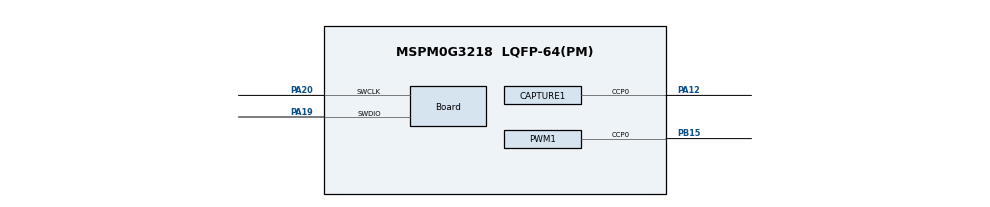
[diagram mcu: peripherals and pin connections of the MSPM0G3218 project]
//@cliArgs --device "MSPM0G321X" --package "LQFP-64(PM)" --part "Default"
//@v2CliArgs --device "MSPM0G3218" --package "LQFP-64(PM)"
// @cliArgs --board /ti/boards/LP_MSPM0G3218 --rtos nortos

/**
 * Import the modules used in this configuration.
 */
const CAPTURE  = scripting.addModule("/ti/driverlib/CAPTURE", {}, false);
const CAPTURE1 = CAPTURE.addInstance();
const PWM      = scripting.addModule("/ti/driverlib/PWM", {}, false);
const PWM1     = PWM.addInstance();

/**
 * Write custom configuration values to the imported modules.
 */
CAPTURE1.$name                      = "CAPTURE_0";
CAPTURE1.captMode                   = "COMBINED";
CAPTURE1.timerClkPrescale           = 256;
CAPTURE1.timerPeriod                = "524.29 ms";
CAPTURE1.interrupts                 = ["CC1_DN","ZERO"];
CAPTURE1.peripheral.ccp0Pin.$assign = "PA12";

const Board                       = scripting.addModule("/ti/driverlib/Board", {}, false);
Board.peripheral.$assign          = "DEBUGSS";
Board.peripheral.swclkPin.$assign = "PA20";
Board.peripheral.swdioPin.$assign = "PA19";

PWM1.$name                      = "PWM_0";
PWM1.ccIndex                    = [0];
PWM1.clockPrescale              = 256;
PWM1.peripheral.ccp0Pin.$assign = "PB15";
PWM1.PWM_CHANNEL_0.$name        = "ti_driverlib_pwm_PWMTimerCC0";
PWM1.PWM_CHANNEL_0.dutyCycle    = 50;

const SYSCTL                 = scripting.addModule("/ti/driverlib/SYSCTL", {}, false);
SYSCTL.forceDefaultClkConfig = true;
SYSCTL.clockTreeEn           = true;

const ProjectConfig              = scripting.addModule("/ti/project_config/ProjectConfig", {}, false);
ProjectConfig.migrationCondition = true;
